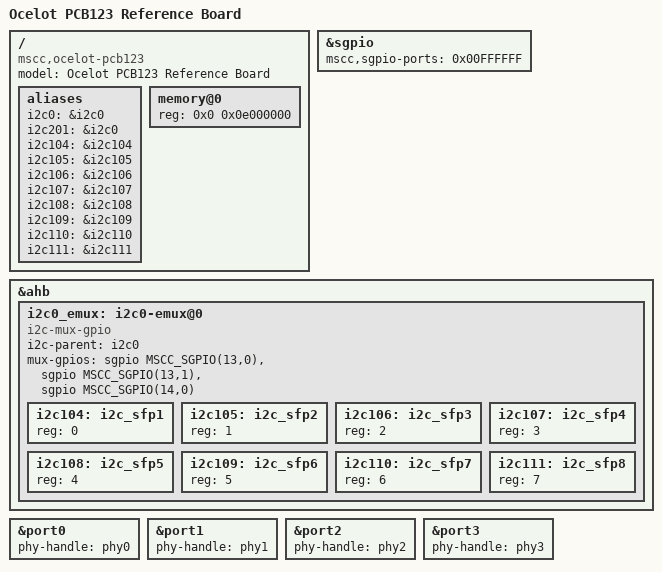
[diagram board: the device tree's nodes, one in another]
// SPDX-License-Identifier: (GPL-2.0 OR MIT)
/* Copyright (c) 2017 Microsemi Corporation */

/dts-v1/;

#include <dt-bindings/gpio/mscc-sgpio.h>
#include "ocelot_common.dtsi"

/ {
	model = "Ocelot PCB123 Reference Board";
	compatible = "mscc,ocelot-pcb123", "mscc,ocelot";

	aliases {
	    i2c0   = &i2c0;
	    i2c201 = &i2c0;
	    i2c104 = &i2c104;
	    i2c105 = &i2c105;
	    i2c106 = &i2c106;
	    i2c107 = &i2c107;
	    i2c108 = &i2c108;
	    i2c109 = &i2c109;
	    i2c110 = &i2c110;
	    i2c111 = &i2c111;
	};

	memory@0 {
		device_type = "memory";
		reg = <0x0 0x0e000000>;
	};
};

&sgpio {
	status = "okay";
	mscc,sgpio-ports = <0x00FFFFFF>;
};

&ahb {
	i2c0_emux: i2c0-emux@0 {
		compatible = "i2c-mux-gpio";
		#address-cells = <1>;
		#size-cells = <0>;
		i2c-parent = <&i2c0>;
		mux-gpios = <&sgpio MSCC_SGPIO(13,0) GPIO_ACTIVE_HIGH>, // p13b0
			    <&sgpio MSCC_SGPIO(13,1) GPIO_ACTIVE_HIGH>, // p13b1
			    <&sgpio MSCC_SGPIO(14,0) GPIO_ACTIVE_HIGH>; // p14b0
		i2c104: i2c_sfp1 {
			reg = <0>;
			#address-cells = <1>;
			#size-cells = <0>;
		};
		i2c105: i2c_sfp2 {
			reg = <1>;
			#address-cells = <1>;
			#size-cells = <0>;
		};
		i2c106: i2c_sfp3 {
			reg = <2>;
			#address-cells = <1>;
			#size-cells = <0>;
		};
		i2c107: i2c_sfp4 {
			reg = <3>;
			#address-cells = <1>;
			#size-cells = <0>;
		};
		i2c108: i2c_sfp5 {
			reg = <4>;
			#address-cells = <1>;
			#size-cells = <0>;
		};
		i2c109: i2c_sfp6 {
			reg = <5>;
			#address-cells = <1>;
			#size-cells = <0>;
		};
		i2c110: i2c_sfp7 {
			reg = <6>;
			#address-cells = <1>;
			#size-cells = <0>;
		};
		i2c111: i2c_sfp8 {
			reg = <7>;
			#address-cells = <1>;
			#size-cells = <0>;
		};
	};
};

&port0 {
	phy-handle = <&phy0>;
};

&port1 {
	phy-handle = <&phy1>;
};

&port2 {
	phy-handle = <&phy2>;
};

&port3 {
	phy-handle = <&phy3>;
};
